# f29h85x_cpu_per_cfg_regs register map
Vendor: Texas Instruments
Peripheral module from a debugger description file (folder C29).
Registers are 32-bit, read-write, no defined reset value unless marked. A register's access mark holds for its fields unless they carry their own. Offsets are as the file gives them; lines under a group give offsets from that group; [hi:lo] are bit positions; {n}, {i} and the like mark numbered series; 'fields as' and 'values as' point back to an identical list; <NAME> marks a mode.

## CPU_PER_CFG_REGS — CPU PER CFG Registers
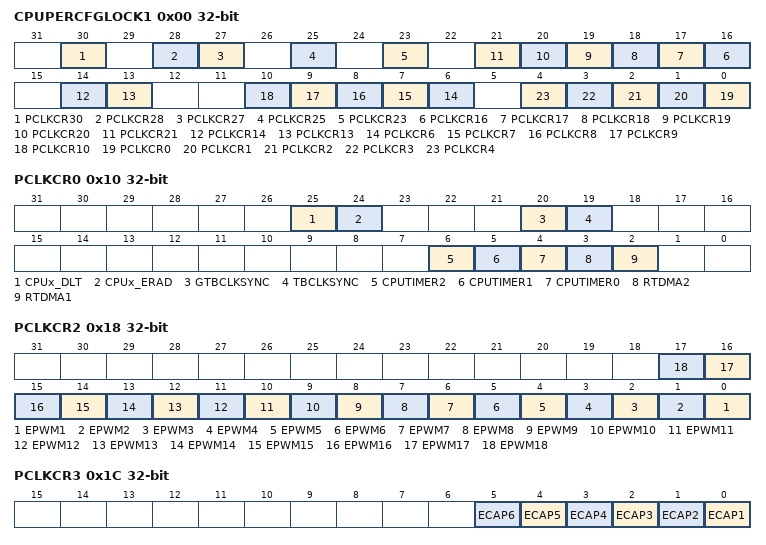
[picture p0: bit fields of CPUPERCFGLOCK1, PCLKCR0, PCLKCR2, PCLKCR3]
0x00 CPUPERCFGLOCK1 — Lock bit for CPUx_PER_CFG registers
  [30] PCLKCR30 — Lock bit for PCLKCR30 Register
  [28] PCLKCR28 — Lock bit for PCLKCR28 Register
  [27] PCLKCR27 — Lock bit for PCLKCR27 Register
  [25] PCLKCR25 — Lock bit for PCLKCR25 Register
  [23] PCLKCR23 — Lock bit for PCLKCR23 Register
  [n] PCLKCR{n} (n=16..21) — Lock bit for PCLKCR{n} Register
  [14] PCLKCR14 — Lock bit for PCLKCR14 Register
  [13] PCLKCR13 — Lock bit for PCLKCR13 Register
  [n] PCLKCR{n} (n=6..10) — Lock bit for PCLKCR{n} Register
  [n] PCLKCR{n} (n=0..4) — Lock bit for PCLKCR{n} Register
0x04 CPUPERCFGLOCK2 — Lock bit for CPUx_PER_CFG registers
  [0] PCLKCR32 — Lock bit for PCLKCR32 Register
0x10 PCLKCR0 — Peripheral Clock Gating Registers
  [25] CPUx_DLT — CPUx_DLT Clock Enable Bit
  [24] CPUx_ERAD — CPUx_ERAD Clock Enable Bit
  [20] GTBCLKSYNC — GTBCLKSYNC Clock Enable Bit
  [19] TBCLKSYNC — TBCLKSYNC Clock Enable Bit
  [6] CPUTIMER2 — CPUTIMER2 Clock Enable Bit
  [5] CPUTIMER1 — CPUTIMER1 Clock Enable Bit
  [4] CPUTIMER0 — CPUTIMER0 Clock Enable Bit
  [3] RTDMA2 — RTDMA2 Clock Enable Bit
  [2] RTDMA1 — RTDMA1 Clock Enable Bit
0x14 PCLKCR1 — Peripheral Clock Gating Register - EMIF
  [0] EMIF1 — EMIF1 Clock Enable bit
0x18 PCLKCR2 — Peripheral Clock Gating Register - EPWM
  [n-1] EPWM{n} (n=1..18) — EPWM{n} Clock Enable bit
0x1C PCLKCR3 — Peripheral Clock Gating Register - ECAP
  [n-1] ECAP{n} (n=1..6) — ECAP{n} Clock Enable bit
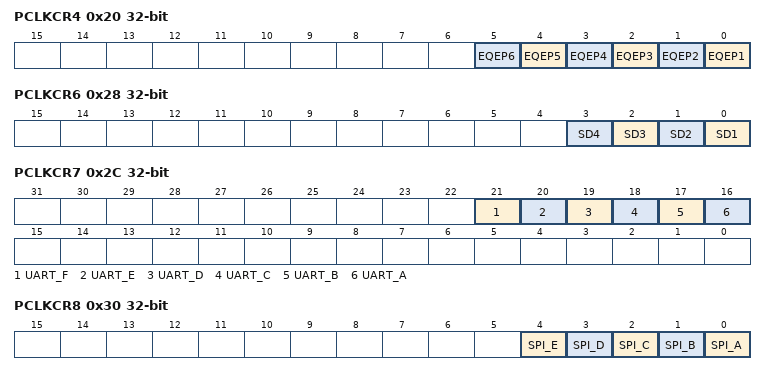
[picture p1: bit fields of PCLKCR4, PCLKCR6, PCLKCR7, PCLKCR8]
0x20 PCLKCR4 — Peripheral Clock Gating Register - EQEP
  [n-1] EQEP{n} (n=1..6) — EQEP{n} Clock Enable bit
0x28 PCLKCR6 — Peripheral Clock Gating Register - SDFM
  [n-1] SD{n} (n=1..4) — SD{n} Clock Enable bit
0x2C PCLKCR7 — Peripheral Clock Gating Register - SCI, UART
  [21] UART_F — UART_F Clock Enable bit
  [20] UART_E — UART_E Clock Enable bit
  [19] UART_D — UART_D Clock Enable bit
  [18] UART_C — UART_C Clock Enable bit
  [17] UART_B — UART_B Clock Enable bit
  [16] UART_A — UART_A Clock Enable bit
0x30 PCLKCR8 — Peripheral Clock Gating Register - SPI
  [4] SPI_E — SPI_E Clock Enable bit
  [3] SPI_D — SPI_D Clock Enable bit
  [2] SPI_C — SPI_C Clock Enable bit
  [1] SPI_B — SPI_B Clock Enable bit
  [0] SPI_A — SPI_A Clock Enable bit
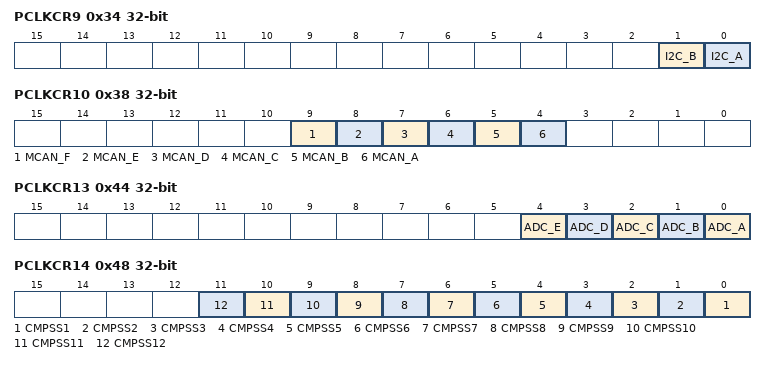
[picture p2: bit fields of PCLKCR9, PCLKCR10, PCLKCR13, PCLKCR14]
0x34 PCLKCR9 — Peripheral Clock Gating Register - I2C
  [1] I2C_B — I2C_B Clock Enable bit
  [0] I2C_A — I2C_A Clock Enable bit
0x38 PCLKCR10 — Peripheral Clock Gating Register - CAN
  [9] MCAN_F — MCAN_F Clock Enable bit
  [8] MCAN_E — MCAN_E Clock Enable bit
  [7] MCAN_D — MCAN_D Clock Enable bit
  [6] MCAN_C — MCAN_C Clock Enable bit
  [5] MCAN_B — MCAN_B Clock Enable bit
  [4] MCAN_A — MCAN_A Clock Enable bit
0x44 PCLKCR13 — Peripheral Clock Gating Register - ADC
  [4] ADC_E — ADC_E Clock Enable bit
  [3] ADC_D — ADC_D Clock Enable bit
  [2] ADC_C — ADC_C Clock Enable bit
  [1] ADC_B — ADC_B Clock Enable bit
  [0] ADC_A — ADC_A Clock Enable bit
0x48 PCLKCR14 — Peripheral Clock Gating Register - CMPSS
  [n-1] CMPSS{n} (n=1..12) — CMPSS{n} Clock Enable bit
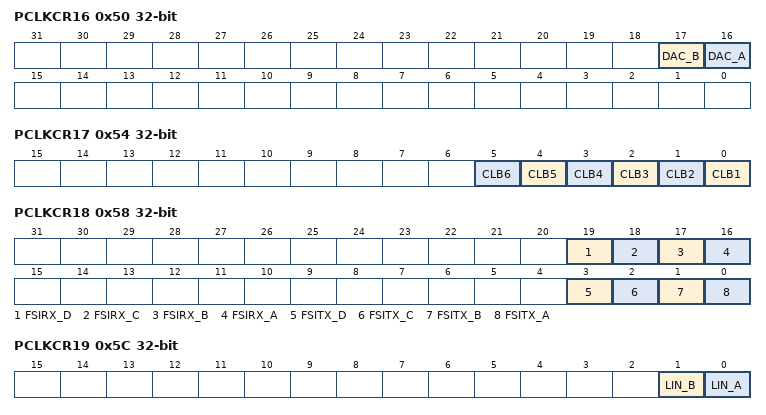
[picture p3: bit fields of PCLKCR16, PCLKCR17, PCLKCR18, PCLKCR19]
0x50 PCLKCR16 — Peripheral Clock Gating Register Buf_DAC
  [17] DAC_B — DAC_B Clock Enable bit
  [16] DAC_A — DAC_A Clock Enable bit
0x54 PCLKCR17 — Peripheral Clock Gating Register - CLB
  [n-1] CLB{n} (n=1..6) — CLB{n} Clock Enable bit
0x58 PCLKCR18 — Peripheral Clock Gating Register - FSI
  [19] FSIRX_D — FSIRX_D Clock Enable bit
  [18] FSIRX_C — FSIRX_C Clock Enable bit
  [17] FSIRX_B — FSIRX_B Clock Enable bit
  [16] FSIRX_A — FSIRX_A Clock Enable bit
  [3] FSITX_D — FSITX_D Clock Enable bit
  [2] FSITX_C — FSITX_C Clock Enable bit
  [1] FSITX_B — FSITX_B Clock Enable bit
  [0] FSITX_A — FSITX_A Clock Enable bit
0x5C PCLKCR19 — Peripheral Clock Gating Register - LIN
  [1] LIN_B — LIN_B Clock Enable bit
  [0] LIN_A — LIN_A Clock Enable bit
0x60 PCLKCR20 — Peripheral Clock Gating Register - PMBUS
  [0] PMBUS_A — PMBUS_A Clock Enable bit
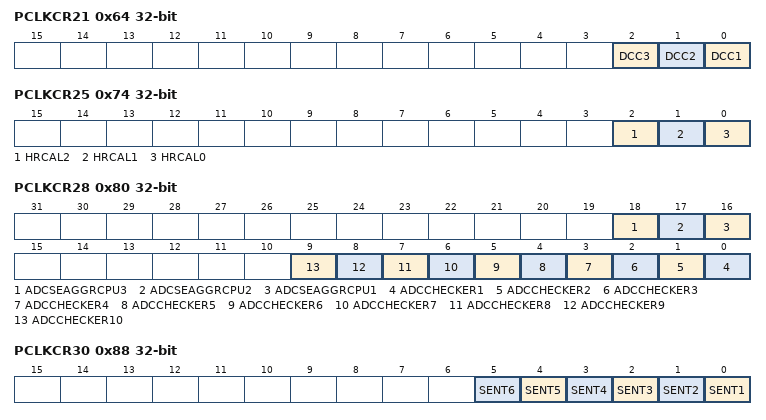
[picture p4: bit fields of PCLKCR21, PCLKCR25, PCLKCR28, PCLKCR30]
0x64 PCLKCR21 — Peripheral Clock Gating Register - DCC
  [2] DCC3 — DCC3 Clock Enable Bit
  [1] DCC2 — DCC2 Clock Enable Bit
  [0] DCC1 — DCC1 Clock Enable Bit
0x6C PCLKCR23 — Peripheral Clock Gating Register - EtherCAT
  [0] ETHERCAT — ETHERCAT Clock Enable Bit
0x74 PCLKCR25 — Peripheral Clock Gating Register - HRCAL0,1,2
  [2] HRCAL2 — HRCAL2 Clock Enable Bit
  [1] HRCAL1 — HRCAL1 Clock Enable Bit
  [0] HRCAL0 — HRCAL0 Clock Enable Bit
0x7C PCLKCR27 — Peripheral Clock Gating Register - EPG
  [0] EPG1 — EPG1 Clock Enable Bit
0x80 PCLKCR28 — Peripheral Clock Gating Register - ADCCHECKER
  [18] ADCSEAGGRCPU3 — ADCSEAGGRCPU3 Clock Enable bit
  [17] ADCSEAGGRCPU2 — ADCSEAGGRCPU2 Clock Enable bit
  [16] ADCSEAGGRCPU1 — ADCSEAGGRCPU1 Clock Enable bit
  [n-1] ADCCHECKER{n} (n=1..10) — ADCCHECKER{n} Clock Enable bit
0x88 PCLKCR30 — Peripheral Clock Gating Register - SENT
  [n-1] SENT{n} (n=1..6) — SENT{n} Clock Enable bit
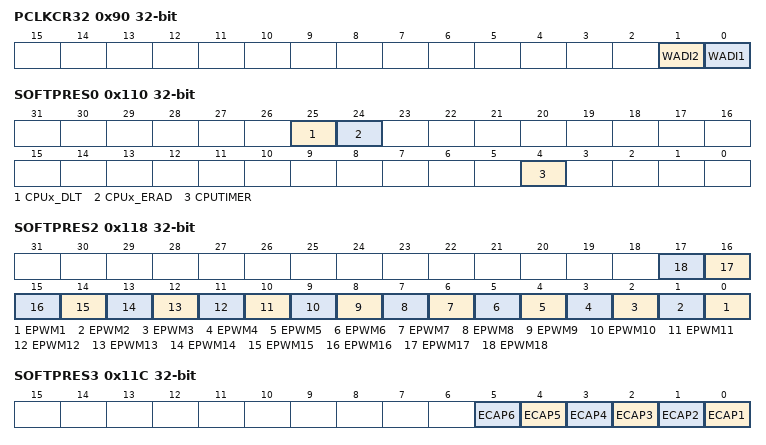
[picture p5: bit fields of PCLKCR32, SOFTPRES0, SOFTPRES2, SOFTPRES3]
0x90 PCLKCR32 — Peripheral Clock Gating Register - WADI
  [1] WADI2 — WADI2 Clock Enable bit
  [0] WADI1 — WADI1 Clock Enable bit
0x110 SOFTPRES0 — Processing Block Software Reset register
  [25] CPUx_DLT — CPUx_DLT Module reset bit
  [24] CPUx_ERAD — CPUx_ERAD Module reset bit
  [4] CPUTIMER — Reset bit for modules CPUTIMER0, COUTIMER1 and CPUTIMER2
0x114 SOFTPRES1 — EMIF Software Reset register
  [0] EMIF1 — EMIF1 software reset bit
0x118 SOFTPRES2 — EPWM Software Reset register
  [n-1] EPWM{n} (n=1..18) — EPWM{n} software reset bit
0x11C SOFTPRES3 — ECAP Software Reset register
  [n-1] ECAP{n} (n=1..6) — ECAP{n} software reset bit
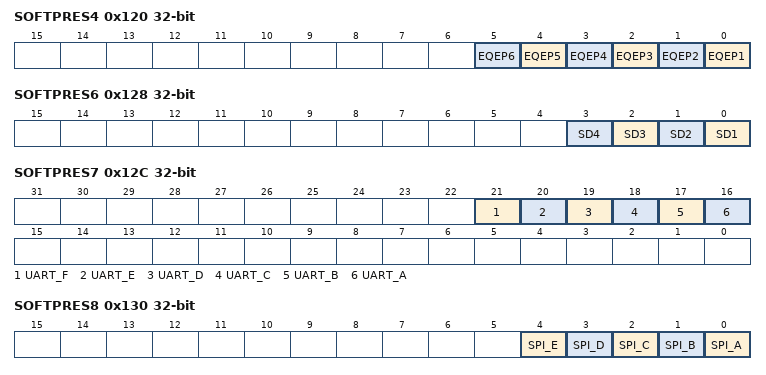
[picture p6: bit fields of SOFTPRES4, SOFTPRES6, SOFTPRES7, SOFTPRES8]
0x120 SOFTPRES4 — EQEP Software Reset register
  [n-1] EQEP{n} (n=1..6) — EQEP{n} software reset bit
0x128 SOFTPRES6 — Sigma Delta Software Reset register
  [n-1] SD{n} (n=1..4) — SD{n} software reset bit
0x12C SOFTPRES7 — SCI, UART Software Reset register
  [21] UART_F — UART_F software reset bit
  [20] UART_E — UART_E software reset bit
  [19] UART_D — UART_D software reset bit
  [18] UART_C — UART_C software reset bit
  [17] UART_B — UART_B software reset bit
  [16] UART_A — UART_A software reset bit
0x130 SOFTPRES8 — SPI Software Reset register
  [4] SPI_E — SPI_E software reset bit
  [3] SPI_D — SPI_D software reset bit
  [2] SPI_C — SPI_C software reset bit
  [1] SPI_B — SPI_B software reset bit
  [0] SPI_A — SPI_A software reset bit
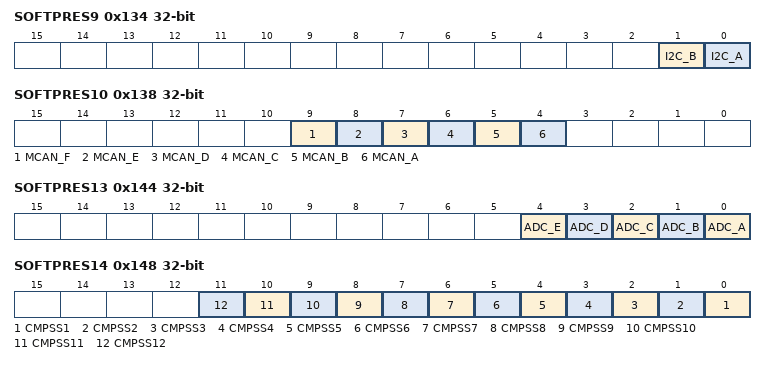
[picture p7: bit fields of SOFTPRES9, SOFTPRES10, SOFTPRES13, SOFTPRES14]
0x134 SOFTPRES9 — I2C Software Reset register
  [1] I2C_B — I2C_B software reset bit
  [0] I2C_A — I2C_A software reset bit
0x138 SOFTPRES10 — CAN Software Reset register
  [9] MCAN_F — MCAN_F software reset bit
  [8] MCAN_E — MCAN_E software reset bit
  [7] MCAN_D — MCAN_D software reset bit
  [6] MCAN_C — MCAN_C software reset bit
  [5] MCAN_B — MCAN_B software reset bit
  [4] MCAN_A — MCAN_A software reset bit
0x144 SOFTPRES13 — ADC Software Reset register
  [4] ADC_E — ADC_E software reset bit
  [3] ADC_D — ADC_D software reset bit
  [2] ADC_C — ADC_C software reset bit
  [1] ADC_B — ADC_B software reset bit
  [0] ADC_A — ADC_A software reset bit
0x148 SOFTPRES14 — CMPSS Software Reset register
  [n-1] CMPSS{n} (n=1..12) — CMPSS{n} software reset bit
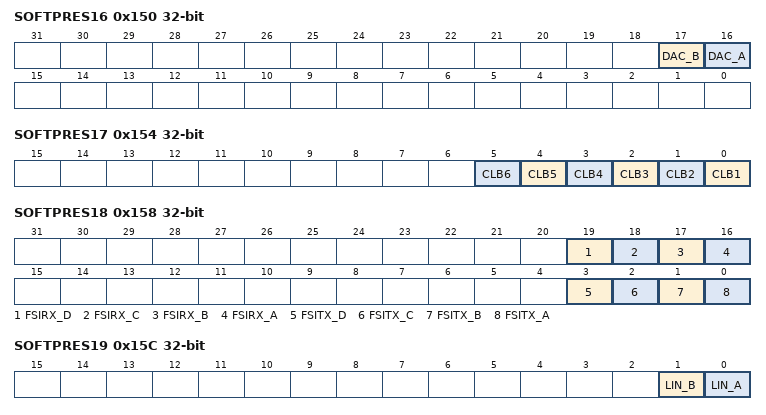
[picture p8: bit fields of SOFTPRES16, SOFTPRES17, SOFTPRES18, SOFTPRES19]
0x150 SOFTPRES16 — DAC Software Reset register
  [17] DAC_B — DAC_B software reset bit
  [16] DAC_A — DAC_A software reset bit
0x154 SOFTPRES17 — CLB Software Reset register
  [n-1] CLB{n} (n=1..6) — CLB{n} software reset bit
0x158 SOFTPRES18 — FSI Software Reset register
  [19] FSIRX_D — FSIRX_D software reset bit
  [18] FSIRX_C — FSIRX_C software reset bit
  [17] FSIRX_B — FSIRX_B software reset bit
  [16] FSIRX_A — FSIRX_A software reset bit
  [3] FSITX_D — FSITX_D software reset bit
  [2] FSITX_C — FSITX_C software reset bit
  [1] FSITX_B — FSITX_B software reset bit
  [0] FSITX_A — FSITX_A software reset bit
0x15C SOFTPRES19 — LIN Software Reset register
  [1] LIN_B — LIN_B software reset bit
  [0] LIN_A — LIN_A software reset bit
0x160 SOFTPRES20 — PMBUS Software Reset register
  [0] PMBUS_A — PMBUS_A software reset bit
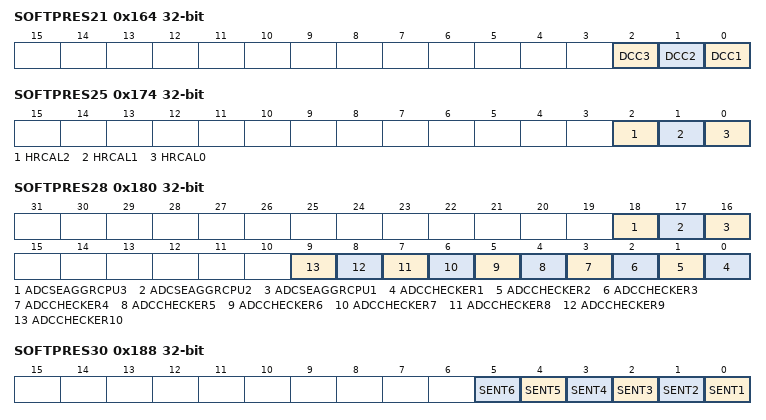
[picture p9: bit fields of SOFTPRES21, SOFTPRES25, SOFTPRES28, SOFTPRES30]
0x164 SOFTPRES21 — DCC Software Reset register
  [2] DCC3 — DCC Module reset bit
  [1] DCC2 — DCC Module reset bit
  [0] DCC1 — DCC Module reset bit
0x16C SOFTPRES23 — ETHERCAT Software Reset register
  [0] ETHERCAT — ETHERCAT Module reset bit
0x174 SOFTPRES25 — HRCAL0,1,2 Software Reset register
  [2] HRCAL2 — HRCAL2 Module reset bit
  [1] HRCAL1 — HRCAL1 Module reset bit
  [0] HRCAL0 — HRCAL0 Module reset bit
0x17C SOFTPRES27 — EPG Software Reset register
  [0] EPG1 — EPG Module Reset Bit
0x180 SOFTPRES28 — ADCCHECKER Software Reset register
  [18] ADCSEAGGRCPU3 — ADCSEAGGRCPU3 software reset bit
  [17] ADCSEAGGRCPU2 — ADCSEAGGRCPU2 software reset bit
  [16] ADCSEAGGRCPU1 — ADCSEAGGRCPU1 software reset bit
  [n-1] ADCCHECKER{n} (n=1..10) — ADCCHECKER{n} software reset bit
0x188 SOFTPRES30 — SENT Software Reset register
  [n-1] SENT{n} (n=1..6) — SENT{n} software reset bit
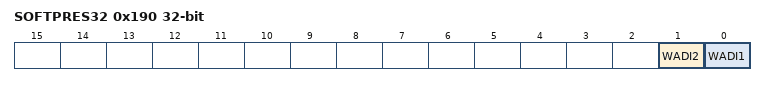
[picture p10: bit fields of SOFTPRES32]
0x190 SOFTPRES32 — WADI Software Reset register
  [1] WADI2 — WADI2 software reset bit
  [0] WADI1 — WADI1 software reset bit
0x1B8 PARITY_TEST_ALT1 — Enables parity test
  [3:0] TESTEN — Parity test enable configuration
